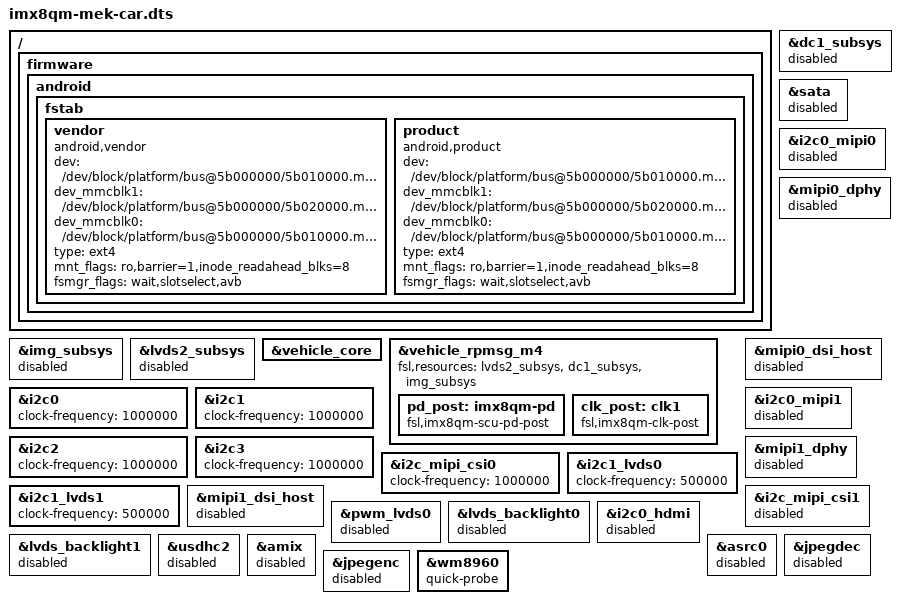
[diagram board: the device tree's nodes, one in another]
// SPDX-License-Identifier: GPL-2.0+
// Copyright NXP 2020

#include "imx8qm-mek-rpmsg.dts"

&img_subsys {
	status = "disabled";
};

&dc1_subsys {
	status = "disabled";
};

&lvds2_subsys {
	status = "disabled";
};

&vehicle_core {
	status = "okay";
};

&vehicle_rpmsg_m4 {
	#address-cells = <2>;
	#size-cells = <2>;
	status = "okay";
	ranges;
	fsl,resources = <&lvds2_subsys>,
			<&dc1_subsys>,
			<&img_subsys>;

	pd_post: imx8qm-pd {
		compatible = "fsl,imx8qm-scu-pd-post";
		#power-domain-cells = <1>;
	};

	clk_post: clk1 {
		compatible = "fsl,imx8qm-clk-post";
		#clock-cells = <2>;
	};
};

/ {
	firmware {
		android {
			fstab {
				/delete-node/ system;
				vendor {
					compatible = "android,vendor";
					/* default emmc node used for GSI */
					dev = "/dev/block/platform/bus@5b000000/5b010000.mmc/by-name/vendor";
					/* sd card node which used if androidboot.boot_device_root=mmcblk1 */
					dev_mmcblk1 = "/dev/block/platform/bus@5b000000/5b020000.mmc/by-name/vendor";
					/* emmc node which used if androidboot.boot_device_root=mmcblk0 */
					dev_mmcblk0 = "/dev/block/platform/bus@5b000000/5b010000.mmc/by-name/vendor";
					type = "ext4";
					mnt_flags = "ro,barrier=1,inode_readahead_blks=8";
					fsmgr_flags = "wait,slotselect,avb";
				};
				product {
					compatible = "android,product";
					/* default emmc node used for GSI */
					dev = "/dev/block/platform/bus@5b000000/5b010000.mmc/by-name/product";
					/* sd card node which used if androidboot.boot_device_root=mmcblk1 */
					dev_mmcblk1 = "/dev/block/platform/bus@5b000000/5b020000.mmc/by-name/product";
					/* emmc node which used if androidboot.boot_device_root=mmcblk0 */
					dev_mmcblk0 = "/dev/block/platform/bus@5b000000/5b010000.mmc/by-name/product";
					type = "ext4";
					mnt_flags = "ro,barrier=1,inode_readahead_blks=8";
					fsmgr_flags = "wait,slotselect,avb";
				};
			};
		};
	};
};

&sata {
	status = "disabled";
};

&i2c0 {
	clock-frequency = <1000000>;
};

&i2c1 {
	clock-frequency = <1000000>;
};

&i2c2 {
	clock-frequency = <1000000>;
};

&i2c3 {
	clock-frequency = <1000000>;
};

&i2c_mipi_csi0 {
	clock-frequency = <1000000>;
};

&i2c1_lvds0 {
	clock-frequency = <500000>;
};

&i2c1_lvds1 {
	clock-frequency = <500000>;
};

&i2c0_mipi0 {
	status = "disabled";
};

&mipi0_dphy {
	status = "disabled";
};

&mipi0_dsi_host {
	status = "disabled";
};

&i2c0_mipi1 {
	status = "disabled";
};

&mipi1_dphy {
	status = "disabled";
};

&mipi1_dsi_host {
	status = "disabled";
};

&i2c_mipi_csi1 {
	status = "disabled";
};

&pwm_lvds0 {
	status = "disabled";
};

&lvds_backlight0 {
	status = "disabled";
};

&lvds_backlight1 {
	status = "disabled";
};

&i2c0_hdmi {
	status = "disabled";
};

&usdhc2 {
	status = "disabled";
};

&amix {
	status = "disabled";
};

&asrc0 {
	status = "disabled";
};

&jpegdec {
	status = "disabled";
};

&jpegenc {
	status = "disabled";
};

&wm8960 {
	quick-probe;
};
